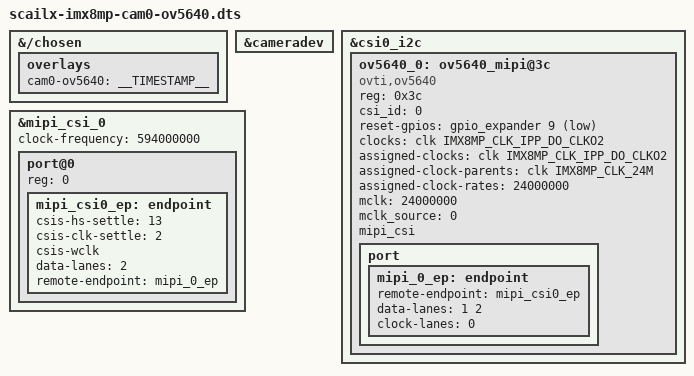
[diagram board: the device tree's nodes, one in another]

// CSI Camera Module 5MP OV5640 on CSI-0

/dts-v1/;
/plugin/;

#include <dt-bindings/clock/imx8mp-clock.h>
#include <dt-bindings/gpio/gpio.h>

&{/chosen} {
	overlays {
		cam0-ov5640 = __TIMESTAMP__;
	};
};

&cameradev {
	status = "okay";
};

&csi0_i2c {
	ov5640_0: ov5640_mipi@3c {
		compatible = "ovti,ov5640";
		reg = <0x3c>;
		csi_id = <0>;
		reset-gpios = <&gpio_expander 9 GPIO_ACTIVE_LOW>;
		clocks = <&clk IMX8MP_CLK_IPP_DO_CLKO2>;
		clock-names = "xclk";
		assigned-clocks = <&clk IMX8MP_CLK_IPP_DO_CLKO2>;
		assigned-clock-parents = <&clk IMX8MP_CLK_24M>;
		assigned-clock-rates = <24000000>;
		mclk = <24000000>;
		mclk_source = <0>;
		mipi_csi;
		status = "okay";

		port {
			mipi_0_ep: endpoint {
				remote-endpoint = <&mipi_csi0_ep>;
				data-lanes = <1 2>;
				clock-lanes = <0>;
			};
		};
	};
};

&mipi_csi_0 {
	#address-cells = <1>;
	#size-cells = <0>;
	clock-frequency = <594000000>;
	status = "okay";

	port@0 {
		reg = <0>;

		mipi_csi0_ep: endpoint {
			csis-hs-settle = <13>;
			csis-clk-settle = <2>;
			csis-wclk;
			data-lanes = <2>;
			remote-endpoint = <&mipi_0_ep>;
		};
	};
};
